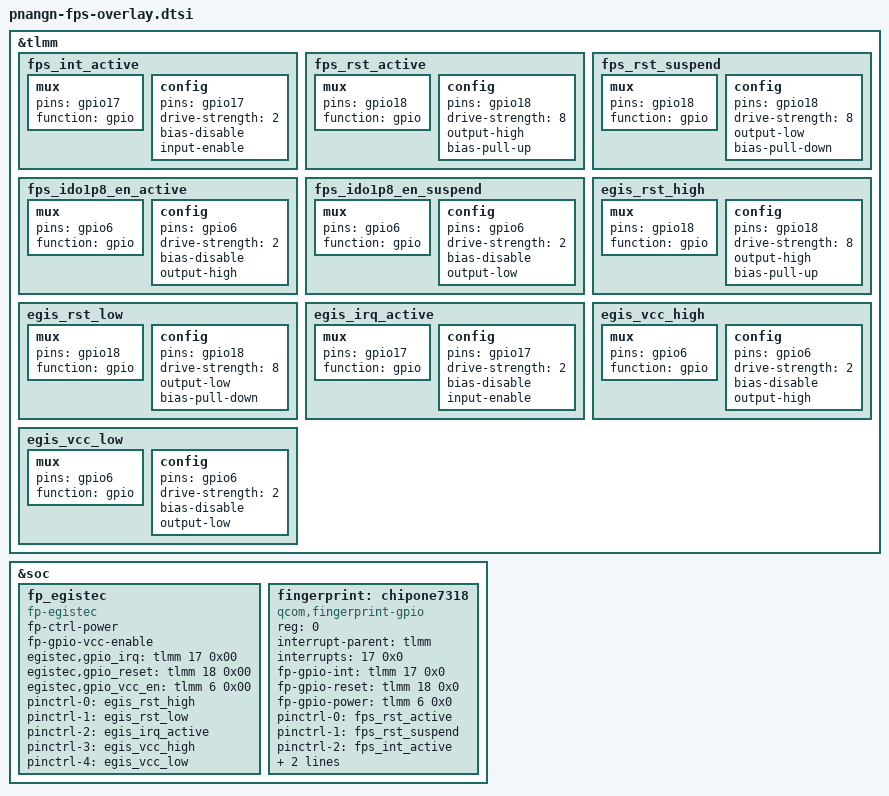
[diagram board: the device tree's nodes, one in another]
&tlmm {
	fps_int_active: fps_int_active {
		/* active state */
		mux {
			pins = "gpio17";
			function = "gpio";
		};

		config {
			pins = "gpio17";
			drive-strength = <2>; /* 2 MA */
			bias-disable;
			input-enable;
		};
	};

	fps_rst_active: fps_rst_active {
		mux {
			pins = "gpio18";
			function = "gpio";
		};

		config {
			pins = "gpio18";
			drive-strength = <8>;
			output-high;
			bias-pull-up;
		};
	};

	fps_rst_suspend: fps_rst_suspend {
		mux {
			pins = "gpio18";
			function = "gpio";
		};
		config {
			pins = "gpio18";
			drive-strength = <8>;
			output-low;
			bias-pull-down;
		};
	};

	fps_ido1p8_en_active: fps_ido1p8_en_active {
		/* active state */
		mux {
			pins = "gpio6";
			function = "gpio";
		};

		config {
			pins = "gpio6";
			drive-strength = <2>; /* 2 MA */
				bias-disable;
				output-high;
		};
	};

	fps_ido1p8_en_suspend: fps_ido1p8_en_suspend {
		/* sleep state */
		mux {
			pins = "gpio6";
			function = "gpio";
		};

		config {
			pins = "gpio6";
			drive-strength = <2>; /* 2 MA */
			bias-disable;
			output-low;
		};
	};

	egis_rst_high: egis_rst_high {
		mux {
			pins = "gpio18";
			function = "gpio";
		};

		config {
			pins = "gpio18";
			drive-strength = <8>;
			output-high;
			bias-pull-up;
		};
	};

	egis_rst_low: egis_rst_low {
		mux {
			pins = "gpio18";
			function = "gpio";
		};
		config {
			pins = "gpio18";
			drive-strength = <8>;
			output-low;
			bias-pull-down;
		};
	};

	egis_irq_active: egis_irq_active {
		mux {
			pins = "gpio17";
			function = "gpio";
		};
		config {
			pins = "gpio17";
			drive-strength = <2>;
			bias-disable;
			input-enable;
		};
	};

	egis_vcc_high: egis_vcc_high {
		mux {
			pins = "gpio6";
			function = "gpio";
		};

		config {
			pins = "gpio6";
			drive-strength = <2>;
			bias-disable;
			output-high;
		};
	};

	egis_vcc_low: egis_vcc_low {
		mux {
			pins = "gpio6";
			function = "gpio";
		};

		config {
			pins = "gpio6";
			drive-strength = <2>;
			bias-disable;
			output-low;
		};
	};
};

&soc {
	fp_egistec {
		status = "ok";
		compatible = "fp-egistec";
		fp-ctrl-power;
		fp-gpio-vcc-enable;
		egistec,gpio_irq = <&tlmm 17 0x00>;
		egistec,gpio_reset = <&tlmm 18 0x00>;
		egistec,gpio_vcc_en = <&tlmm 6 0x00>;
		pinctrl-names = "egis_rst_high", "egis_rst_low", "egis_irq_active","egis_vcc_high","egis_vcc_low";
		pinctrl-0 = <&egis_rst_high>;
		pinctrl-1 = <&egis_rst_low>;
		pinctrl-2 = <&egis_irq_active>;
		pinctrl-3 = <&egis_vcc_high>;
		pinctrl-4 = <&egis_vcc_low>;
	};
	//chipone side fps
	fingerprint: chipone7318 {
		compatible = "qcom,fingerprint-gpio";
		status = "ok";
		reg = <0>;
		interrupt-parent = <&tlmm>;
		interrupts = <17 0x0>;
		fp-gpio-int = <&tlmm 17 0x0>;
		fp-gpio-reset = <&tlmm 18 0x0>;
		fp-gpio-power = <&tlmm 6 0x0>;
		pinctrl-names = "fps_rst_active","fps_rst_suspend","fps_int_active","fps_ido1p8_en_active","fps_ido1p8_en_suspend";
		pinctrl-0 = <&fps_rst_active>;
		pinctrl-1 = <&fps_rst_suspend>;
		pinctrl-2 = <&fps_int_active>;
		pinctrl-3 = <&fps_ido1p8_en_active>;
		pinctrl-4 = <&fps_ido1p8_en_suspend>;
	};
};

